# tle984x register map
Vendor: Infineon; File version: 1.9.5
CPU: CM0 r2p1, little endian, no MPU, no FPU, 2 interrupt priority bits
Registers are 32-bit, read-write, reset 0x0 unless marked. A register's access mark holds for its fields unless they carry their own. Offsets are from the block's base; [hi:lo] are bit positions; 'fields as' and 'values as' point back to an identical list.

## HS — High-side switch registers
Base 0x40024000
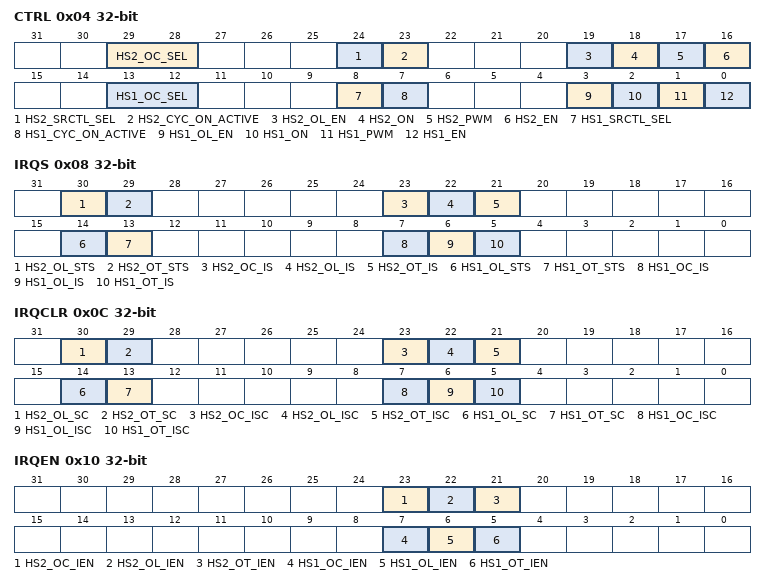
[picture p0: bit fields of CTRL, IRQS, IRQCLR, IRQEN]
0x04 CTRL — High-side driver control register
  [29:28] HS2_OC_SEL — High side 2 overcurrent threshold selection
    0=IOCTH0 (25 mA min.); 1=IOCTH1 (50 mA min.); 2=IOCTH2 (100 mA min.); 3=IOCTH3 (150 mA min.)
  [24] HS2_SRCTL_SEL — High side 2 slew rate control select
    0=SLEW_RATE_1 (Slew rate 10 V/us is enabled); 1=SLEW_RATE_2 (Slew rate 30 V/us is enabled)
  [23] HS2_CYC_ON_ACTIVE — High side 2 cyclic ON driver
    0=OFF (Cyclic ON driver OFF); 1=ON (Cyclic ON driver ON)
  [19] HS2_OL_EN — High side 2 open load detection enable
    0=DISABLE (Disable open load detection); 1=ENABLE (Enable open load detection)
  [18] HS2_ON — High side 2 on
    0=OFF (HS driver off); 1=ON (HS driver on)
  [17] HS2_PWM — High side 2 PWM enable
    0=DISABLE (Disables control by PWM input); 1=ENABLE (Enables control by PWM input)
  [16] HS2_EN — High side 2 enable
    0=DISABLE (HS circuit power off); 1=ENABLE (HS circuit power on)
  [13:12] HS1_OC_SEL — High side 1 overcurrent threshold selection
    values as HS2_OC_SEL
  [8] HS1_SRCTL_SEL — High side 1 slew rate control select
    values as HS2_SRCTL_SEL
  [7] HS1_CYC_ON_ACTIVE — High side 1 cyclic ON driver
    0=OFF (Cyclic ON driver OFF); 1=ON (Cyclic ON driver ON)
  [3] HS1_OL_EN — High side 1 open load detection enable
    values as HS2_OL_EN
  [2] HS1_ON — High side 1 on
    0=OFF (HS driver off); 1=ON (HS driver on)
  [1] HS1_PWM — High side 1 PWM enable
    values as HS2_PWM
  [0] HS1_EN — High side 1 enable
    values as HS2_EN
0x08 IRQS — High-side driver interrupt status register
  [30] HS2_OL_STS — High side 2 open load interrupt status
    0=NO_OPEN_LOAD (No open load condition occurred); 1=OPEN_LOAD (Open load occurred; switch is not automatically shut down. Write sets status)
  [29] HS2_OT_STS — High side 2 overtemperature status
    0=NO_OVERTEMPERATURE (No overtemperature occurred); 1=OVERTEMPERATURE (Overtemperature occurred; switch is automatically shut down. Write sets status)
  [23] HS2_OC_IS — High side 2 overcurrent interrupt status
    0=NO_OVERCURRENT (No overcurrent condition occurred); 1=OVERCURRENT (Overcurrent occurred; switch is automatically shut down. Write sets status)
  [22] HS2_OL_IS — High side 2 open load interrupt status
    0=NORMAL (Normal load); 1=OPEN_LOAD (Open load detected, write sets status)
  [21] HS2_OT_IS — High side 2 overtemperature interrupt status
    values as HS2_OT_STS
  [14] HS1_OL_STS — High side 1 open load interrupt status
    values as HS2_OL_STS
  [13] HS1_OT_STS — High side 1 overtemperature status
    values as HS2_OT_STS
  [7] HS1_OC_IS — High side 1 overcurrent interrupt status
    values as HS2_OC_IS
  [6] HS1_OL_IS — High side 1 open load interrupt status
    values as HS2_OL_IS
  [5] HS1_OT_IS — High side 1 overtemperature interrupt status
    values as HS2_OT_STS
0x0C IRQCLR — High-side driver interrupt status clear register
  [all] fields
    0=NO_CLEAR; 1=CLEAR
  [30] HS2_OL_SC wo — High side 2 open load status clear
  [29] HS2_OT_SC wo — High side 2 overtemperature status clear
  [23] HS2_OC_ISC wo — High side 2 overcurrent interrupt status clear
  [22] HS2_OL_ISC wo — High side 2 open load interrupt status clear
  [21] HS2_OT_ISC wo — High side 2 overtemperature interrupt status clear
  [14] HS1_OL_SC wo — High side 1 open load status clear
  [13] HS1_OT_SC wo — High side 1 overtemperature status clear
  [7] HS1_OC_ISC wo — High side 1 overcurrent interrupt status clear
  [6] HS1_OL_ISC wo — High side 1 open load interrupt status clear
  [5] HS1_OT_ISC wo — High Side 1 overtemperature interrupt status clear
0x10 IRQEN — High-side driver interrupt enable register
  [23] HS2_OC_IEN — High side 2 overcurrent interrupt enable
    0=DISABLE (Disabled); 1=ENABLE
  [22] HS2_OL_IEN — High side 2 open load interrupt enable
    0=DISABLE (Disabled); 1=ENABLE
  [21] HS2_OT_IEN — High side 2 overtemperature interrupt enable
    0=DISABLED; 1=ENABLE
  [7] HS1_OC_IEN — High side 1 overcurrent interrupt enable
    0=DISABLE (Disabled); 1=ENABLE
  [6] HS1_OL_IEN — High side 1 open load interrupt enable
    0=DISABLE (Disabled); 1=ENABLE
  [5] HS1_OT_IEN — High Side 1 overtemperature interrupt enable
    0=DISABLED; 1=ENABLE
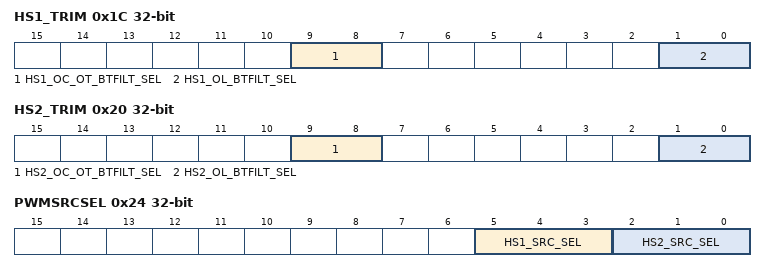
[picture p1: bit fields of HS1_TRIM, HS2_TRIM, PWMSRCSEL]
0x1C HS1_TRIM — High-side driver 1 TRIM register
  [9:8] HS1_OC_OT_BTFILT_SEL — Blanking time filter select for HS1 overcurrent/overtemperature detection
    0=4 us filter time; 1=8 us filter time; 2=16 us filter time; 3=32 us filter time
  [1:0] HS1_OL_BTFILT_SEL — Blanking time filter select for HS1 open load detection
    0=2_us (4 us filter time); 1=4_us (8 us filter time); 2=8_us (16 us filter time); 3=16_us (32 us filter time)
0x20 HS2_TRIM — High-side driver 2 TRIM register
  [9:8] HS2_OC_OT_BTFILT_SEL — Blanking time/filter select for HS2 overcurrent/overtemperature detection
    values as HS1_TRIM.HS1_OC_OT_BTFILT_SEL
  [1:0] HS2_OL_BTFILT_SEL — Blanking time filter select for HS2 open load detection
    values as HS1_TRIM.HS1_OL_BTFILT_SEL
0x24 PWMSRCSEL — High-side PWM source selection register
  [5:3] HS1_SRC_SEL — HS1 PWM source selection
    0=CC60 (PWM output of CCU6 (CC60)); 1=CC61 (PWM output of CCU6 (CC61)); 2=CC62 (PWM output of CCU6 (CC62)); 3=COUT60 (PWM output of CCU6 (COUT60)); 4=COUT61 (PWM output of CCU6 (COUT61)); 5=COUT62 (PWM output of CCU6 (COUT62)); 6=T3OUT (PWM output of GPT12)
  [2:0] HS2_SRC_SEL — HS2 PWM source selection
    values as HS1_SRC_SEL
